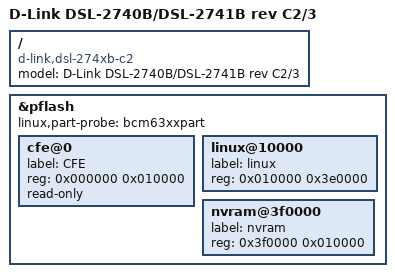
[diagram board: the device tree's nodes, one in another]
/dts-v1/;

/include/ "bcm6358.dtsi"

/ {
	model = "D-Link DSL-2740B/DSL-2741B rev C2/3";
	compatible = "d-link,dsl-274xb-c2", "brcm,bcm6358";
};

&pflash {
	status = "ok";

	linux,part-probe = "bcm63xxpart";

	cfe@0 {
		label = "CFE";
		reg = <0x000000 0x010000>;
		read-only;
	};

	linux@10000 {
		label = "linux";
		reg = <0x010000 0x3e0000>;
	};

	nvram@3f0000 {
		label = "nvram";
		reg = <0x3f0000 0x010000>;
	};
};
